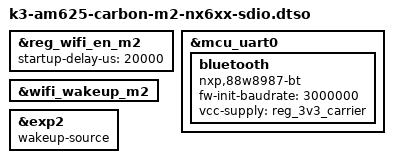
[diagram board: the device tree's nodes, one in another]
// SPDX-License-Identifier: GPL-2.0
/*
 * M.2 SDIO NX6xx module
 * Copyright (C) 2024 Ezurio LLC
 */

/dts-v1/;
/plugin/;

#include "k3-am625-carbon-m2-sdio.dtsi"

&reg_wifi_en_m2 {
	startup-delay-us = <20000>;
};

&mcu_uart0 {
	bluetooth {
		compatible = "nxp,88w8987-bt";
		fw-init-baudrate = <3000000>;
		vcc-supply = <&reg_3v3_carrier>;
	};
};

&wifi_wakeup_m2 {
	status = "okay";
};

&exp2 {
	wakeup-source;
};
